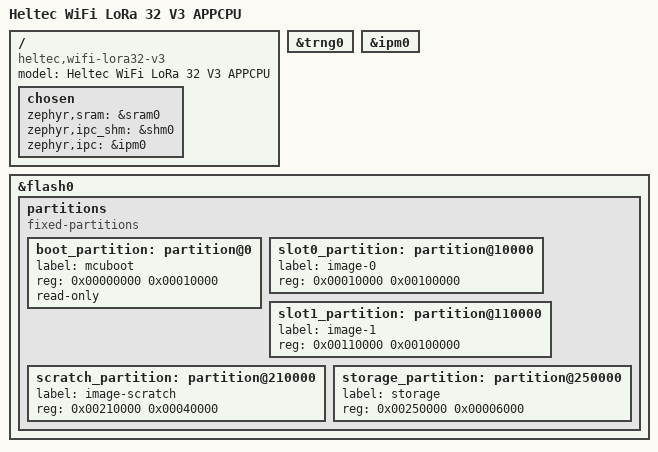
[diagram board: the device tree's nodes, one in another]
/*
 * SPDX-License-Identifier: GPL-3.0-or-later
 * SPDX-FileCopyrightText: The contributors to the LICHEN project
 *
 * Heltec WiFi LoRa 32 V3 — APPCPU stub (secondary core, unused by LICHEN).
 */

/dts-v1/;

#include <espressif/esp32s3/esp32s3_appcpu.dtsi>

/ {
	model = "Heltec WiFi LoRa 32 V3 APPCPU";
	compatible = "heltec,wifi-lora32-v3";

	chosen {
		zephyr,sram    = &sram0;
		zephyr,ipc_shm = &shm0;
		zephyr,ipc     = &ipm0;
	};
};

&trng0 { status = "okay"; };
&ipm0  { status = "okay"; };

&flash0 {
	status = "okay";
	partitions {
		compatible = "fixed-partitions";
		#address-cells = <1>;
		#size-cells = <1>;

		boot_partition: partition@0 {
			label = "mcuboot";
			reg = <0x00000000 0x00010000>;
			read-only;
		};
		slot0_partition: partition@10000 {
			label = "image-0";
			reg = <0x00010000 0x00100000>;
		};
		slot1_partition: partition@110000 {
			label = "image-1";
			reg = <0x00110000 0x00100000>;
		};
		scratch_partition: partition@210000 {
			label = "image-scratch";
			reg = <0x00210000 0x00040000>;
		};
		storage_partition: partition@250000 {
			label = "storage";
			reg = <0x00250000 0x00006000>;
		};
	};
};
